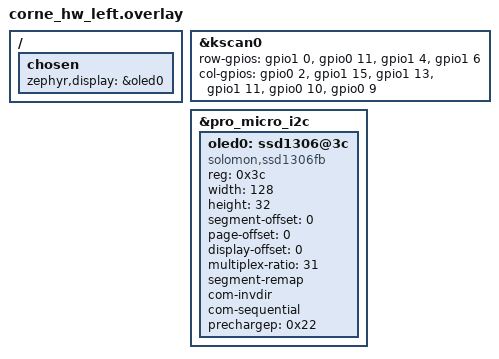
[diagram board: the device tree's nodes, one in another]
/*
 * Copyright (c) 2020 The ZMK Contributors
 *
 * SPDX-License-Identifier: MIT
 */

#include <dt-bindings/pinctrl/nrf-pinctrl.h>
#include <dt-bindings/i2c/i2c.h>
#include "corne_hw.dtsi"

/ {
    chosen {
        zephyr,display = &oled0;
    };
};

&kscan0 {
  row-gpios = <&gpio1 0  (GPIO_ACTIVE_HIGH | GPIO_PULL_DOWN)>,
                    <&gpio0 11 (GPIO_ACTIVE_HIGH | GPIO_PULL_DOWN)>,
                    <&gpio1 4  (GPIO_ACTIVE_HIGH | GPIO_PULL_DOWN)>,
                    <&gpio1 6  (GPIO_ACTIVE_HIGH | GPIO_PULL_DOWN)>;

                  /* Cols: P0.09, P0.10, P1.11, P1.13, P1.15, P0.02 */
        col-gpios = <&gpio0 2  GPIO_ACTIVE_HIGH>,
                    <&gpio1 15 GPIO_ACTIVE_HIGH>,
                    <&gpio1 13 GPIO_ACTIVE_HIGH>,
                    <&gpio1 11 GPIO_ACTIVE_HIGH>,
                    <&gpio0 10 GPIO_ACTIVE_HIGH>,
                    <&gpio0 9  GPIO_ACTIVE_HIGH>;
};

// OLED configuration - using pro_micro_i2c on Nice Nano
// Pins: SDA=P0.17, SCL=P0.20 (board defaults)
&pro_micro_i2c {
    status = "okay";

    oled0: ssd1306@3c {
        compatible = "solomon,ssd1306fb";
        reg = <0x3c>;
        width = <128>;
        height = <32>;
        segment-offset = <0>;
        page-offset = <0>;
        display-offset = <0>;
        multiplex-ratio = <31>;
        segment-remap;
        com-invdir;
        com-sequential;
        prechargep = <0x22>;
    };
};

// pinctrl configuration is handled by the board (Nice Nano)

